# GD32H7xx register map
File version: 1.0
CPU: CM7 r1p2, little endian, MPU, FPU, 4 interrupt priority bits
Registers are 32-bit, read-write, reset 0x0 unless marked. A register's access mark holds for its fields unless they carry their own. Offsets are from the block's base; [hi:lo] are bit positions; {n}, {i} and the like mark numbered series; 'fields as' and 'values as' point back to an identical list.

## SYSCFG — System and memory architectur
Base 0x58000400
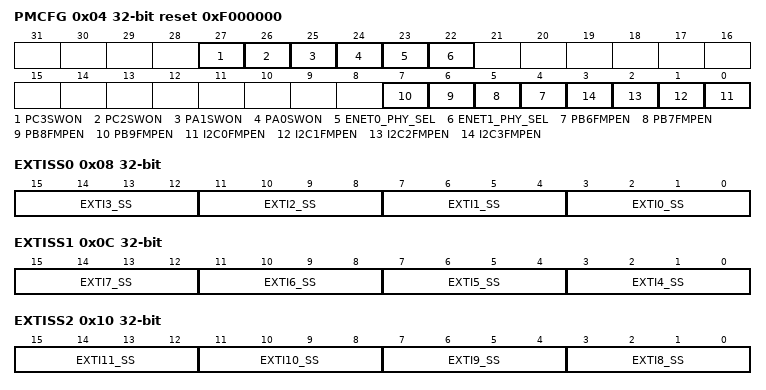
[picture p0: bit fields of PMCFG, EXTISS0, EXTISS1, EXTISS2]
0x04 PMCFG reset 0xF000000 — Peripheral mode configuration register
  [27] PC3SWON — PC3 switch open
  [26] PC2SWON — PC2 switch open
  [25] PA1SWON — PA1 switch open
  [24] PA0SWON — PA0 switch open
  [23] ENET0_PHY_SEL — Ethernet0 PHY interface selection
  [22] ENET1_PHY_SEL — Ethernet1 PHY interface selection
  [n-2] PB{n}FMPEN (n=6..9) — PB{n} pin Fm+ mode enable
  [n] I2C{n}FMPEN (n=0..3) — I2C{n} Fm+
0x08 EXTISS0 — EXTI sources selection register 0
  [4n+3:4n] EXTI{n}_SS (n=0..3) — EXTI {n} sources selection
0x0C EXTISS1 — EXTI sources selection register 1
  [4n-13:4n-16] EXTI{n}_SS (n=4..7) — EXTI {n} sources selection
0x10 EXTISS2 — EXTI sources selection register 2
  [4n-29:4n-32] EXTI{n}_SS (n=8..11) — EXTI {n} sources selection
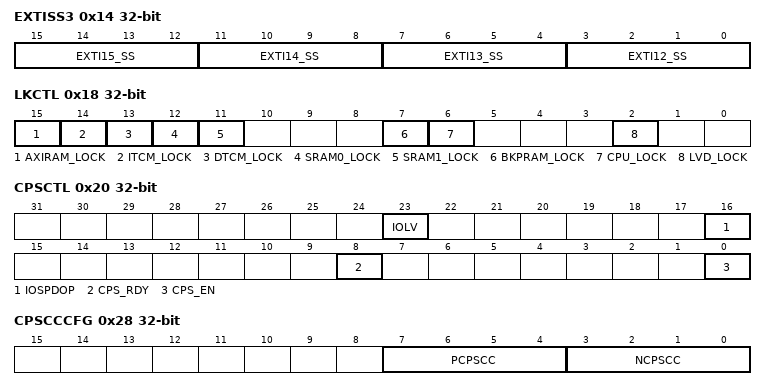
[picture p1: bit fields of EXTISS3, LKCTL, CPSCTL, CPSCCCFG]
0x14 EXTISS3 — EXTI sources selection register 3
  [4n-45:4n-48] EXTI{n}_SS (n=12..15) — EXTI {n} sources selection
0x18 LKCTL — Lockup control register
  [15] AXIRAM_LOCK — Region 0 AXI-SRAM ECC double error lock bit
  [14] ITCM_LOCK — Region 0 ITCM-RAM ECC double error lock bit
  [13] DTCM_LOCK — Region 0 DTCM ECC double error lock bit
  [12] SRAM0_LOCK — Region 1 SRAM0 ECC double error lockup bit
  [11] SRAM1_LOCK — Region 1 SRAM1 ECC double error lockup bit
  [7] BKPRAM_LOCK — Region 2 backup SRAM ECC double error lockup bit
  [6] CPU_LOCK — CPU lockup bit
  [2] LVD_LOCK — Low voltage detector lockup bit
0x20 CPSCTL access per field — I/O compensation control register
  [23] IOLV ro — I/O in low voltage state
  [16] IOSPDOP rw — I/O speed optimization, High-speed at low-voltage
  [8] CPS_RDY ro — Compensation cell ready flag
  [0] CPS_EN rw — I/O compensation cell enable
0x28 CPSCCCFG — I/O compensation cell code configuration register
  [7:4] PCPSCC — PMOS compensation cell code
  [3:0] NCPSCC — NMOS compensation cell code
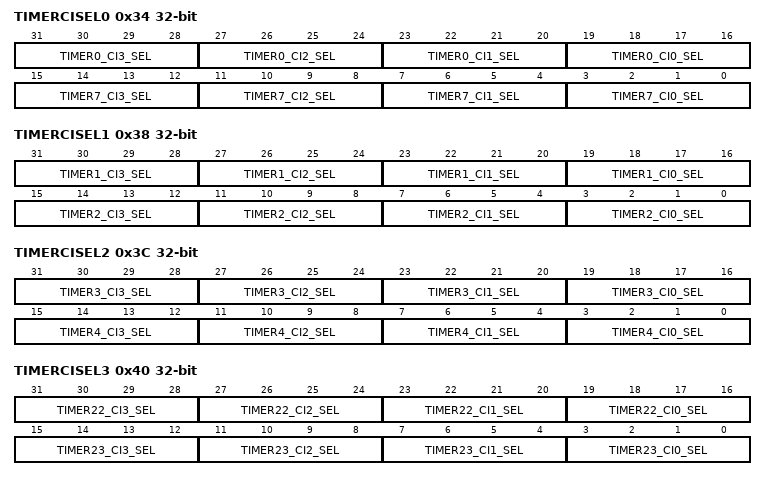
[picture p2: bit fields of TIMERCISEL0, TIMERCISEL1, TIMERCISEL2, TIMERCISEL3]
0x34 TIMERCISEL0 — Timer input selection register 0
  [4n+19:4n+16] TIMER0_CI{n}_SEL (n=0..3) — Selects TIMER0_CI{n} input selection
  [4n+3:4n] TIMER7_CI{n}_SEL (n=0..3) — Selects TIMER7_CI{n} input selection
0x38 TIMERCISEL1 — Timer input selection register 1
  [4n+19:4n+16] TIMER1_CI{n}_SEL (n=0..3) — TIMER1_CI{n} input selection
  [4n+3:4n] TIMER2_CI{n}_SEL (n=0..3) — TIMER2_CI{n} input selection
0x3C TIMERCISEL2 — Timer input selection register 2
  [4n+19:4n+16] TIMER3_CI{n}_SEL (n=0..3) — TIMER3_CI{n} input selection
  [4n+3:4n] TIMER4_CI{n}_SEL (n=0..3) — TIMER4_CI{n} input selection
0x40 TIMERCISEL3 — Timer input selection register 3
  [4n+19:4n+16] TIMER22_CI{n}_SEL (n=0..3) — TIMER22_CI{n} input selection
  [4n+3:4n] TIMER23_CI{n}_SEL (n=0..3) — TIMER23_CI{n} input selection
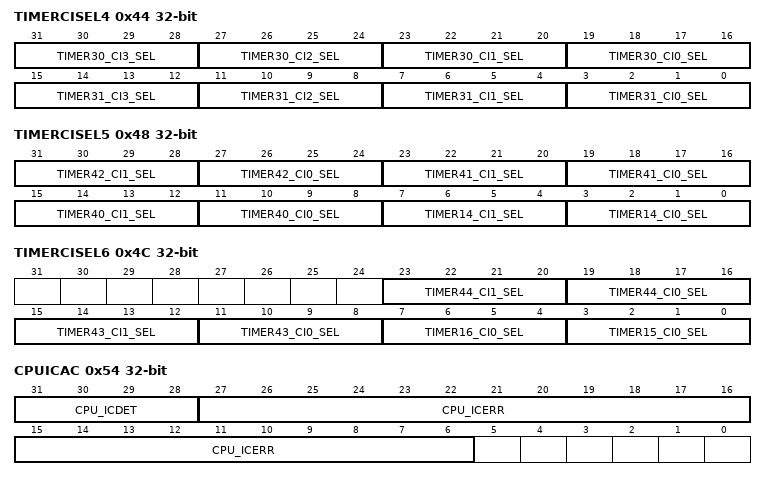
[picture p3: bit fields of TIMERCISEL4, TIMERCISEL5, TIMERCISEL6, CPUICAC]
0x44 TIMERCISEL4 — Timer input selection register 4
  [4n+19:4n+16] TIMER30_CI{n}_SEL (n=0..3) — TIMER30_CI{n} input selection
  [4n+3:4n] TIMER31_CI{n}_SEL (n=0..3) — TIMER31_CI{n} input selection
0x48 TIMERCISEL5 — Timer input selection register 5
  [31:28] TIMER42_CI1_SEL — Selects TIMER42_CI1 input
  [27:24] TIMER42_CI0_SEL — Selects TIMER42_CI0 input
  [23:20] TIMER41_CI1_SEL — Selects TIMER41_CI1 input
  [19:16] TIMER41_CI0_SEL — Selects TIMER41_CI0 input
  [15:12] TIMER40_CI1_SEL — Selects TIMER40_CI1 input
  [11:8] TIMER40_CI0_SEL — Selects TIMER40_CI0 input
  [7:4] TIMER14_CI1_SEL — Selects TIMER14_CI1 input
  [3:0] TIMER14_CI0_SEL — Selects TIMER14_CI0 input
0x4C TIMERCISEL6 — Timer input selection register 6
  [23:20] TIMER44_CI1_SEL — Selects TIMER44_CI1 input
  [19:16] TIMER44_CI0_SEL — Selects TIMER44_CI0 input
  [15:12] TIMER43_CI1_SEL — Selects TIMER43_CI1 input
  [11:8] TIMER43_CI0_SEL — Selects TIMER43_CI0 input
  [7:4] TIMER16_CI0_SEL — Selects TIMER16_CI0 input
  [3:0] TIMER15_CI0_SEL — Selects TIMER15_CI0 input
0x54 CPUICAC ro — CPU ICACHE error status registe
  [31:28] CPU_ICDET — The ICACHE error detection information
  [27:6] CPU_ICERR — The ICACHE error bank information
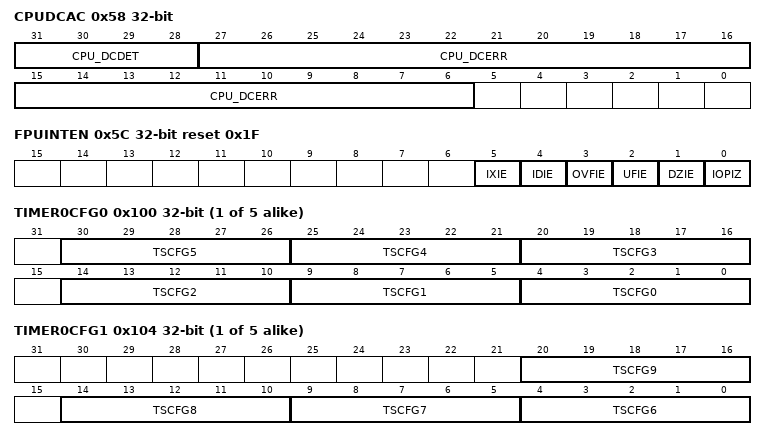
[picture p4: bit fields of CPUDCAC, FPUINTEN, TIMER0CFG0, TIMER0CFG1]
0x58 CPUDCAC ro — CPU DCACHE error status register
  [31:28] CPU_DCDET — The DCACHE error detection information
  [27:6] CPU_DCERR — The DCACHE error bank information
0x5C FPUINTEN reset 0x1F — FPU interrupt enable register
  [5] IXIE — Inexact interrupt enable bit
  [4] IDIE — Input denormal interrupt enable bit
  [3] OVFIE — Overflow interrupt enable bit
  [2] UFIE — Underflow interrupt enable bit
  [1] DZIE — Divide by 0 interrupt enable bit
  [0] IOPIZ — Invalid operation interrupt enable bit
0x64 SRAMCFG0 — SYSCFG SRAM configuration register 0
  [1:0] SECURE_SRAM_SIZE — These bits indicate the size of secure sram
0x68 SRAMCFG1 — SYSCFG SRAM configuration register 1
  [0] TCM_WAITSTATE — TCM wait state configuration
{0x100+0xC*i} TIMER{i}CFG0 (i=0..4) — TIMER{i} configuration register 0
  [30:26] TSCFG5 — Event mode configuration
  [25:21] TSCFG4 — Pause mode configuration
  [20:16] TSCFG3 — Restart mode configuration
  [14:10] TSCFG2 — Quadrature decoder mode 2 configuration
  [9:5] TSCFG1 — Quadrature decoder mode 1 configuration
  [4:0] TSCFG0 — Quadrature decoder mode 0 configuration
{0x104+0xC*i} TIMER{i}CFG1 (i=0..4) — TIMER{i} configuration register 1
  [20:16] TSCFG9 — Non-quadrature decoder mode 1 configuration
  [14:10] TSCFG8 — Non-quadrature decoder mode 0 configuration
  [9:5] TSCFG7 — Restart or event mode configuration
  [4:0] TSCFG6 — External clock mode 0 configuration
{0x108+0xC*i} TIMER{i}CFG2 (i=0..4) — TIMER{i} configuration register 2
  [20:16] TSCFG15 — Internal trigger input source configuration
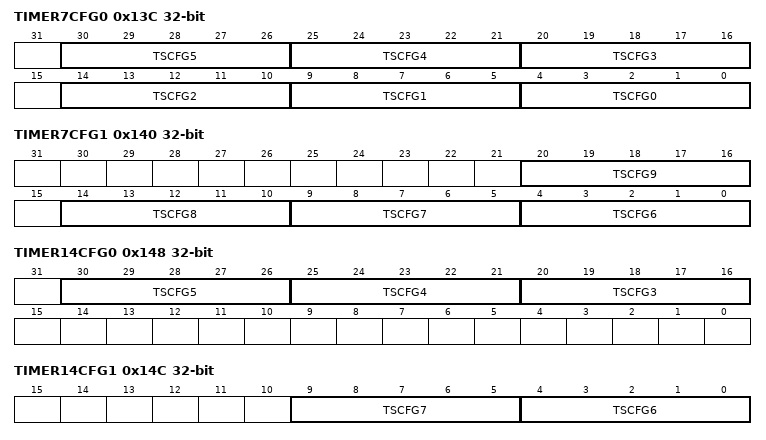
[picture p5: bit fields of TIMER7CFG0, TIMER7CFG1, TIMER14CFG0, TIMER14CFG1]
0x13C TIMER7CFG0 — TIMER7 configuration register 0
  fields as TIMER0CFG0
0x140 TIMER7CFG1 — TIMER7 configuration register 1
  fields as TIMER0CFG1
0x144 TIMER7CFG2 — TIMER7 configuration register 2
  [20:16] TSCFG15 — Internal trigger input source configuration
0x148 TIMER14CFG0 — TIMER14 configuration register 0
  [30:26] TSCFG5 — Event mode configuration
  [25:21] TSCFG4 — Pause mode configuration
  [20:16] TSCFG3 — Restart mode configuration
0x14C TIMER14CFG1 — TIMER14 configuration register 1
  [9:5] TSCFG7 — Restart or event mode configuration
  [4:0] TSCFG6 — External clock mode 0 configuration
0x150 TIMER14CFG2 — TIMER14 configuration register 2
  [20:16] TSCFG15 — Internal trigger input source configuration
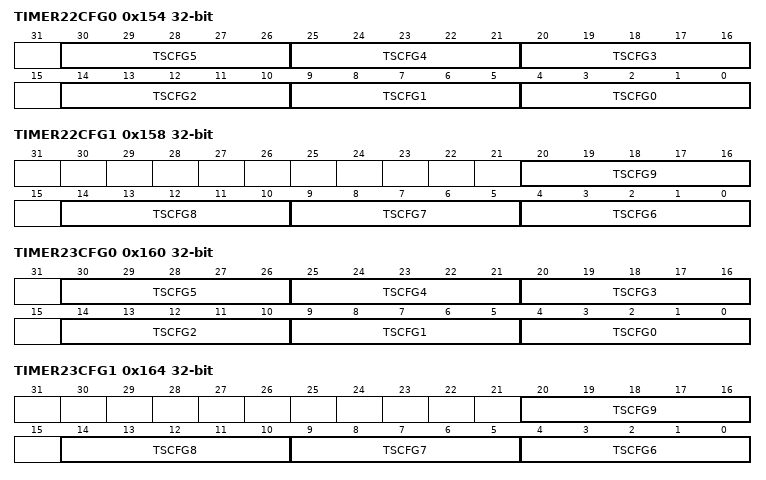
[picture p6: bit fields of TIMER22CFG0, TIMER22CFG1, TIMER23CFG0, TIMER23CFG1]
0x154 TIMER22CFG0 — TIMER22 configuration register 0
  fields as TIMER0CFG0
0x158 TIMER22CFG1 — TIMER22 configuration register 1
  fields as TIMER0CFG1
0x15C TIMER22CFG2 — TIMER22 configuration register 2
  [20:16] TSCFG15 — Internal trigger input source configuration
0x160 TIMER23CFG0 — TIMER23 configuration register 0
  fields as TIMER0CFG0
0x164 TIMER23CFG1 — TIMER23 configuration register 1
  fields as TIMER0CFG1
0x168 TIMER23CFG2 — TIMER23 configuration register 2
  [20:16] TSCFG15 — Internal trigger input source configuration
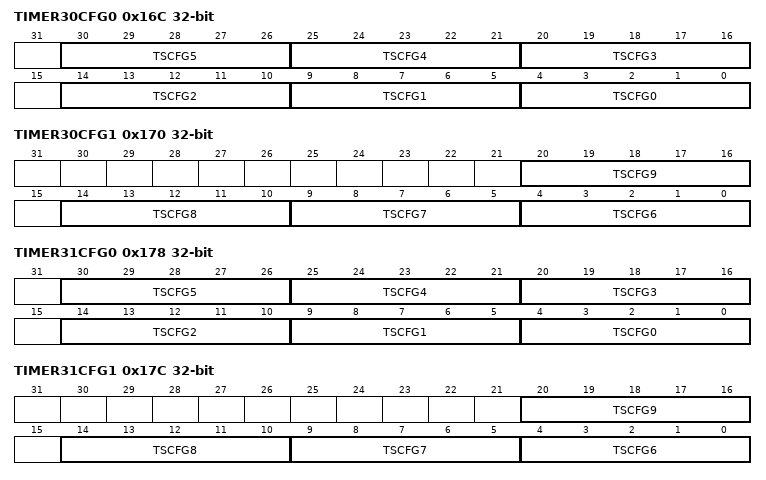
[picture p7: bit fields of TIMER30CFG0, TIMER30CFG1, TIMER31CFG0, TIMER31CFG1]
0x16C TIMER30CFG0 — TIMER30 configuration register 0
  fields as TIMER0CFG0
0x170 TIMER30CFG1 — TIMER30 configuration register 1
  fields as TIMER0CFG1
0x174 TIMER30CFG2 — TIMER30 configuration register 2
  [20:16] TSCFG15 — Internal trigger input source configuration
0x178 TIMER31CFG0 — TIMER31 configuration register 0
  fields as TIMER0CFG0
0x17C TIMER31CFG1 — TIMER31 configuration register 1
  fields as TIMER0CFG1
0x180 TIMER31CFG2 — TIMER31 configuration register 2
  [20:16] TSCFG15 — Internal trigger input source configuration
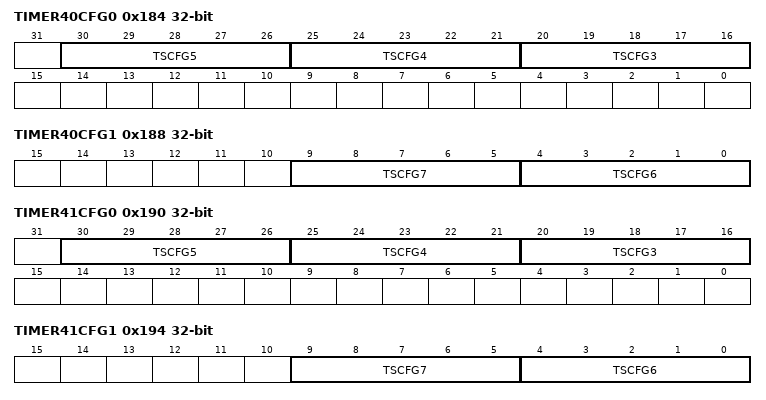
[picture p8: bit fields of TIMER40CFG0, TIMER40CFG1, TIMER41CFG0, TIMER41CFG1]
0x184 TIMER40CFG0 — TIMER40 configuration register 0
  fields as TIMER14CFG0
0x188 TIMER40CFG1 — TIMER40 configuration register 1
  fields as TIMER14CFG1
0x18C TIMER40CFG2 — TIMER40 configuration register 2
  [20:16] TSCFG15 — Internal trigger input source configuration
0x190 TIMER41CFG0 — TIMER41 configuration register 0
  fields as TIMER14CFG0
0x194 TIMER41CFG1 — TIMER41 configuration register 1
  fields as TIMER14CFG1
0x198 TIMER41CFG2 — TIMER41 configuration register 2
  [20:16] TSCFG15 — Internal trigger input source configuration
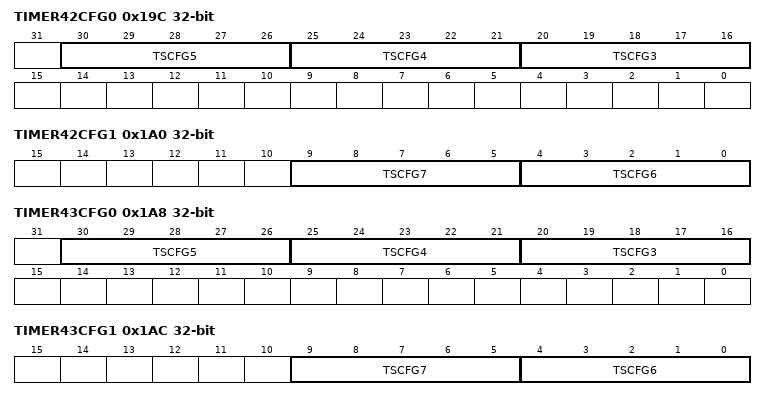
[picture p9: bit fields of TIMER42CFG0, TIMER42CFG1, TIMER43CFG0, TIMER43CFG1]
0x19C TIMER42CFG0 — TIMER42 configuration register 0
  fields as TIMER14CFG0
0x1A0 TIMER42CFG1 — TIMER42 configuration register 1
  fields as TIMER14CFG1
0x1A4 TIMER42CFG2 — TIMER42 configuration register 2
  [20:16] TSCFG15 — Internal trigger input source configuration
0x1A8 TIMER43CFG0 — TIMER43 configuration register 0
  fields as TIMER14CFG0
0x1AC TIMER43CFG1 — TIMER43 configuration register 1
  fields as TIMER14CFG1
0x1B0 TIMER43CFG2 — TIMER43 configuration register 2
  [20:16] TSCFG15 — Internal trigger input source configuration
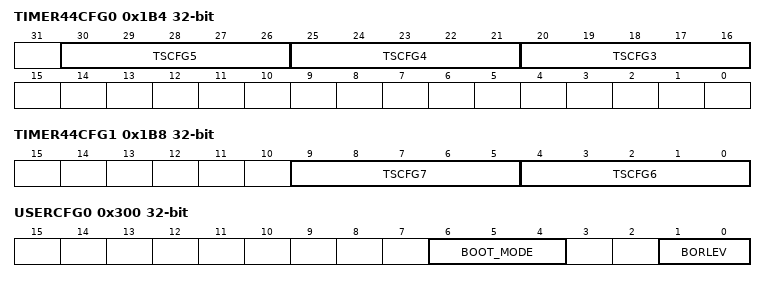
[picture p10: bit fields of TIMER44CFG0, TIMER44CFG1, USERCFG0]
0x1B4 TIMER44CFG0 — TIMER44 configuration register 0
  fields as TIMER14CFG0
0x1B8 TIMER44CFG1 — TIMER44 configuration register 1
  fields as TIMER14CFG1
0x1BC TIMER44CFG2 — TIMER44 configuration register 2
  [20:16] TSCFG15 — Internal trigger input source configuration
0x300 USERCFG0 ro — User configuration register 0
  [6:4] BOOT_MODE
  [1:0] BORLEV — BOR Brownout reset threshold level
0x304 USERCFG1 ro — User configuration register 1
  [31:24] ANA_VERSION — The analog version signal
